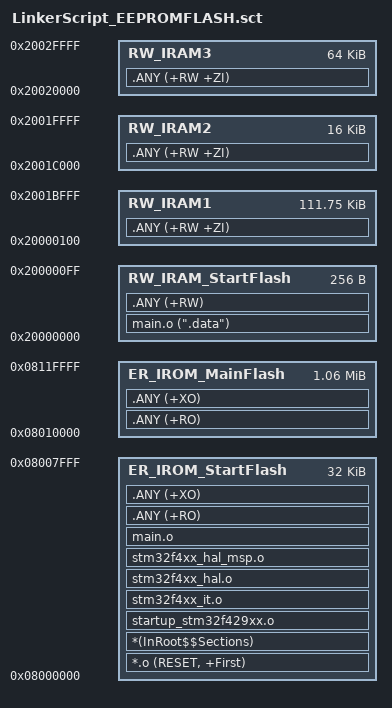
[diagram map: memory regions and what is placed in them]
; *************************************************************
; *** Scatter-Loading Description File generated by uVision ***
; *************************************************************

LR_IROM_StartFlash 0x08000000 0x00008000  {    ; load region size_region
  ER_IROM_StartFlash 0x08000000 0x00008000  {  ; load address = execution address  ;(Sector0 and Sector1)
   *.o (RESET, +First)
   *(InRoot$$Sections)
   
   startup_stm32f429xx.o
   stm32f4xx_it.o
   stm32f4xx_hal.o
   stm32f4xx_hal_msp.o
   main.o
   .ANY (+RO)
   .ANY (+XO)
  }
  
  RW_IRAM_StartFlash 0x20000000 0x00000100  {	; RW data
   main.o (".data") ;or main.o (+RW)
   .ANY (+RW)
  }
}

LR_IROM_MainFlash 0x08010000 0x00110000  {    ; load region size_region
  ER_IROM_MainFlash 0x08010000 0x00110000  {  ; load address = execution address  ;(Sector4 to Sector23)
	.ANY (+RO)
	.ANY (+XO)
  }
  
  RW_IRAM1 0x20000100 0x0001BF00  {	; RW data
   .ANY (+RW +ZI)
  }
  RW_IRAM2 0x2001C000 0x00004000  {	; RW data
   .ANY (+RW +ZI)
  }
  RW_IRAM3 0x20020000 0x00010000  {	; RW data
   .ANY (+RW +ZI)
  }
}
